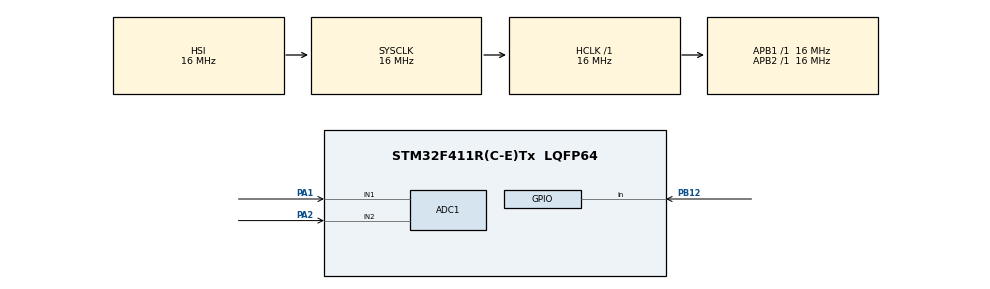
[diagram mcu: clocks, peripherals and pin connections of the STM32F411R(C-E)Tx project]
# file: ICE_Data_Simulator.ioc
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ADC1.Channel-0\#ChannelRegularConversion=ADC_CHANNEL_1
ADC1.NbrOfConversionFlag=1
ADC1.Rank-0\#ChannelRegularConversion=1
ADC1.SamplingTime-0\#ChannelRegularConversion=ADC_SAMPLETIME_3CYCLES
ADC1.master=1
Mcu.Family=STM32F4
Mcu.Name=STM32F411R(C-E)Tx
Mcu.Package=LQFP64
NVIC.PriorityGroup=NVIC_PRIORITYGROUP_4
PA1.Signal=ADCx_IN1
PA2.Signal=ADCx_IN2
PB12.Signal=GPIO_Input
ProjectManager.HeapSize=0x200
ProjectManager.StackSize=0x400
ProjectManager.TargetToolchain=Makefile
RCC.AHBFreq_Value=16000000
RCC.APB1Freq_Value=16000000
RCC.APB2Freq_Value=16000000
RCC.CortexFreq_Value=16000000
RCC.HSE_VALUE=25000000
RCC.HSI_VALUE=16000000
RCC.LSE_VALUE=32768
RCC.SYSCLKFreq_VALUE=16000000
RCC.VCOOutputFreq_Value=192000000
SH.ADCx_IN1.0=ADC1_IN1,IN1
SH.ADCx_IN2.0=ADC1_IN2,IN2
board=custom

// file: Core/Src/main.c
/* USER CODE BEGIN Header */
/**
  ******************************************************************************
  * @file           : main.c
  * @brief          : Main program body
  ******************************************************************************
  * @attention
  *
  * Copyright (c) 2026 STMicroelectronics.
  * All rights reserved.
  *
  * This software is licensed under terms that can be found in the LICENSE file
  * in the root directory of this software component.
  * If no LICENSE file comes with this software, it is provided AS-IS.
  *
  ******************************************************************************
  */
/* USER CODE END Header */
#include "main.h"

/* USER CODE BEGIN Includes */
#include "simulator_main.h"
/* USER CODE END Includes */

ADC_HandleTypeDef hadc1;

void SystemClock_Config(void);
static void MX_GPIO_Init(void);
static void MX_ADC1_Init(void);

int main(void)
{

  /* MCU Configuration--------------------------------------------------------*/

  /* Reset of all peripherals, Initializes the Flash interface and the Systick. */
  HAL_Init();

  /* Configure the system clock */
  SystemClock_Config();

  /* Initialize all configured peripherals */
  MX_GPIO_Init();
  MX_ADC1_Init();

  /* Infinite loop */
  while (1)
  {

  }
}

void SystemClock_Config(void)
{
  RCC_OscInitTypeDef RCC_OscInitStruct = {0};
  RCC_ClkInitTypeDef RCC_ClkInitStruct = {0};

  /** Configure the main internal regulator output voltage
  */
  __HAL_RCC_PWR_CLK_ENABLE();
  __HAL_PWR_VOLTAGESCALING_CONFIG(PWR_REGULATOR_VOLTAGE_SCALE1);

  /** Initializes the RCC Oscillators according to the specified parameters
  * in the RCC_OscInitTypeDef structure.
  */
  RCC_OscInitStruct.OscillatorType = RCC_OSCILLATORTYPE_HSI;
  RCC_OscInitStruct.HSIState = RCC_HSI_ON;
  RCC_OscInitStruct.HSICalibrationValue = RCC_HSICALIBRATION_DEFAULT;
  RCC_OscInitStruct.PLL.PLLState = RCC_PLL_NONE;
  if (HAL_RCC_OscConfig(&RCC_OscInitStruct) != HAL_OK)
  {
    Error_Handler();
  }

  /** Initializes the CPU, AHB and APB buses clocks
  */
  RCC_ClkInitStruct.ClockType = RCC_CLOCKTYPE_HCLK|RCC_CLOCKTYPE_SYSCLK
                              |RCC_CLOCKTYPE_PCLK1|RCC_CLOCKTYPE_PCLK2;
  RCC_ClkInitStruct.SYSCLKSource = RCC_SYSCLKSOURCE_HSI;
  RCC_ClkInitStruct.AHBCLKDivider = RCC_SYSCLK_DIV1;
  RCC_ClkInitStruct.APB1CLKDivider = RCC_HCLK_DIV1;
  RCC_ClkInitStruct.APB2CLKDivider = RCC_HCLK_DIV1;

  if (HAL_RCC_ClockConfig(&RCC_ClkInitStruct, FLASH_LATENCY_0) != HAL_OK)
  {
    Error_Handler();
  }
}

static void MX_ADC1_Init(void)
{

  ADC_ChannelConfTypeDef sConfig = {0};

  /** Configure the global features of the ADC (Clock, Resolution, Data Alignment and number of conversion)
  */
  hadc1.Instance = ADC1;
  hadc1.Init.ClockPrescaler = ADC_CLOCK_SYNC_PCLK_DIV2;
  hadc1.Init.Resolution = ADC_RESOLUTION_10B;
  hadc1.Init.ScanConvMode = DISABLE;
  hadc1.Init.ContinuousConvMode = DISABLE;
  hadc1.Init.DiscontinuousConvMode = DISABLE;
  hadc1.Init.ExternalTrigConvEdge = ADC_EXTERNALTRIGCONVEDGE_NONE;
  hadc1.Init.ExternalTrigConv = ADC_SOFTWARE_START;
  hadc1.Init.DataAlign = ADC_DATAALIGN_RIGHT;
  hadc1.Init.NbrOfConversion = 1;
  hadc1.Init.DMAContinuousRequests = DISABLE;
  hadc1.Init.EOCSelection = ADC_EOC_SINGLE_CONV;
  if (HAL_ADC_Init(&hadc1) != HAL_OK)
  {
    Error_Handler();
  }

  /** Configure for the selected ADC regular channel its corresponding rank in the sequencer and its sample time.
  */
  sConfig.Channel = ADC_CHANNEL_1;
  sConfig.Rank = 1;
  sConfig.SamplingTime = ADC_SAMPLETIME_3CYCLES;
  if (HAL_ADC_ConfigChannel(&hadc1, &sConfig) != HAL_OK)
  {
    Error_Handler();
  }

}

static void MX_GPIO_Init(void)
{
  GPIO_InitTypeDef GPIO_InitStruct = {0};

  /* GPIO Ports Clock Enable */
  __HAL_RCC_GPIOC_CLK_ENABLE();
  __HAL_RCC_GPIOH_CLK_ENABLE();
  __HAL_RCC_GPIOA_CLK_ENABLE();
  __HAL_RCC_GPIOB_CLK_ENABLE();
  __HAL_RCC_GPIOD_CLK_ENABLE();

  /*Configure GPIO pins : PC13 PC14 PC15 PC0
                           PC1 PC2 PC3 PC4
                           PC5 PC6 PC7 PC8
                           PC9 PC10 PC11 PC12 */
  GPIO_InitStruct.Pin = GPIO_PIN_13|GPIO_PIN_14|GPIO_PIN_15|GPIO_PIN_0
                          |GPIO_PIN_1|GPIO_PIN_2|GPIO_PIN_3|GPIO_PIN_4
                          |GPIO_PIN_5|GPIO_PIN_6|GPIO_PIN_7|GPIO_PIN_8
                          |GPIO_PIN_9|GPIO_PIN_10|GPIO_PIN_11|GPIO_PIN_12;
  GPIO_InitStruct.Mode = GPIO_MODE_ANALOG;
  GPIO_InitStruct.Pull = GPIO_NOPULL;
  HAL_GPIO_Init(GPIOC, &GPIO_InitStruct);

  /*Configure GPIO pins : PH0 PH1 */
  GPIO_InitStruct.Pin = GPIO_PIN_0|GPIO_PIN_1;
  GPIO_InitStruct.Mode = GPIO_MODE_ANALOG;
  GPIO_InitStruct.Pull = GPIO_NOPULL;
  HAL_GPIO_Init(GPIOH, &GPIO_InitStruct);

  /*Configure GPIO pins : PA0 PA3 PA4 PA5
                           PA6 PA7 PA8 PA9
                           PA10 PA11 PA12 PA13
                           PA14 PA15 */
  GPIO_InitStruct.Pin = GPIO_PIN_0|GPIO_PIN_3|GPIO_PIN_4|GPIO_PIN_5
                          |GPIO_PIN_6|GPIO_PIN_7|GPIO_PIN_8|GPIO_PIN_9
                          |GPIO_PIN_10|GPIO_PIN_11|GPIO_PIN_12|GPIO_PIN_13
                          |GPIO_PIN_14|GPIO_PIN_15;
  GPIO_InitStruct.Mode = GPIO_MODE_ANALOG;
  GPIO_InitStruct.Pull = GPIO_NOPULL;
  HAL_GPIO_Init(GPIOA, &GPIO_InitStruct);

  /*Configure GPIO pins : PB0 PB1 PB2 PB10
                           PB13 PB14 PB15 PB3
                           PB4 PB5 PB6 PB7
                           PB8 PB9 */
  GPIO_InitStruct.Pin = GPIO_PIN_0|GPIO_PIN_1|GPIO_PIN_2|GPIO_PIN_10
                          |GPIO_PIN_13|GPIO_PIN_14|GPIO_PIN_15|GPIO_PIN_3
                          |GPIO_PIN_4|GPIO_PIN_5|GPIO_PIN_6|GPIO_PIN_7
                          |GPIO_PIN_8|GPIO_PIN_9;
  GPIO_InitStruct.Mode = GPIO_MODE_ANALOG;
  GPIO_InitStruct.Pull = GPIO_NOPULL;
  HAL_GPIO_Init(GPIOB, &GPIO_InitStruct);

  /*Configure GPIO pin : PB12 */
  GPIO_InitStruct.Pin = GPIO_PIN_12;
  GPIO_InitStruct.Mode = GPIO_MODE_INPUT;
  GPIO_InitStruct.Pull = GPIO_NOPULL;
  HAL_GPIO_Init(GPIOB, &GPIO_InitStruct);

  /*Configure GPIO pin : PD2 */
  GPIO_InitStruct.Pin = GPIO_PIN_2;
  GPIO_InitStruct.Mode = GPIO_MODE_ANALOG;
  GPIO_InitStruct.Pull = GPIO_NOPULL;
  HAL_GPIO_Init(GPIOD, &GPIO_InitStruct);

}

void Error_Handler(void)
{
  __disable_irq();
  while (1)
  {
  }
}
